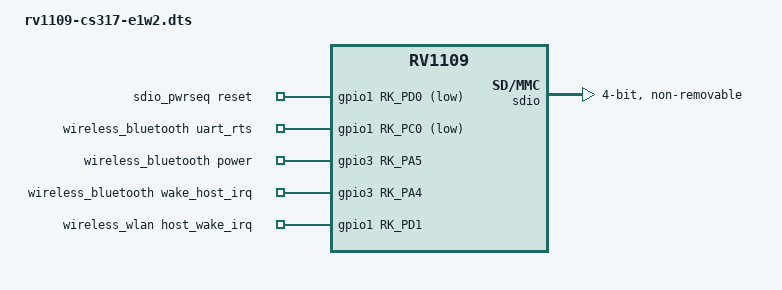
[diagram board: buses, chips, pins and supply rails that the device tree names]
/dts-v1/;

#include "rv1109-cs317.dtsi"

/ {
    sdio_pwrseq: sdio-pwrseq {
		compatible = "mmc-pwrseq-simple";
		pinctrl-names = "default";
		pinctrl-0 = <&wifi_enable_h>;

		/*
		 * On the module itself this is one of these (depending
		 * on the actual card populated):
		 * - SDIO_RESET_L_WL_REG_ON
		 * - PDN (power down when low)
		 */
		reset-gpios = <&gpio1 RK_PD0 GPIO_ACTIVE_LOW>;	//GPIO1_D0----WIFI_REG_ON
	};

    wireless_bluetooth: wireless-bluetooth {
		compatible = "bluetooth-platdata";
		rockchip,pmugrf = <&pmugrf>;
		clocks = <&pmucru CLK_32K_IOE>;
		assigned-clocks = <&pmucru CLK_32K_IOE>;
		assigned-clock-parents = <&pmucru CLK_RTC32K>;
		uart_rts_gpios = <&gpio1 RK_PC0 GPIO_ACTIVE_LOW>;
		pinctrl-names = "default", "rts_gpio";
		pinctrl-0 = <&uart0_rtsn>;
		pinctrl-1 = <&uart0_rtsn_gpio>;
		BT,power_gpio    = <&gpio3 RK_PA5 GPIO_ACTIVE_HIGH>;
		BT,wake_host_irq = <&gpio3 RK_PA4 GPIO_ACTIVE_HIGH>;
		status = "okay";
	};

	wireless_wlan: wireless-wlan {
		compatible = "wlan-platdata";
		rockchip,grf = <&grf>;
		pinctrl-names = "default";
		pinctrl-0 = <&wifi_wake_host>;
		wifi_chip_type = "ap6256";
		/* WIFI,poweren_gpio = <&gpio0 RK_PA6 GPIO_ACTIVE_HIGH>; */
		WIFI,host_wake_irq = <&gpio1 RK_PD1 GPIO_ACTIVE_HIGH>;	//GPIO1_D1----WIFI_WAKE_HOST
		status = "okay";
	};
};

&sdio {
	max-frequency = <200000000>;
	bus-width = <4>;
	cap-sd-highspeed;
	cap-sdio-irq;
	keep-power-in-suspend;
	non-removable;
	rockchip,default-sample-phase = <90>;
	sd-uhs-sdr104;
	supports-sdio;
	mmc-pwrseq = <&sdio_pwrseq>;
	status = "okay";
};

&pinctrl {
    sdio-pwrseq {
		///omit-if-no-ref/
		wifi_enable_h: wifi-enable-h {
			rockchip,pins = <1 RK_PD0 RK_FUNC_GPIO &pcfg_pull_none>;
		};
	};

	wireless-wlan {
		///omit-if-no-ref/
		wifi_wake_host: wifi-wake-host {
			rockchip,pins = <1 RK_PD1 0 &pcfg_pull_up>;
		};
	};
};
